AUTOSAR XML (schema 3-2-1)
package /SeatHeater/HeatRegulator_swc
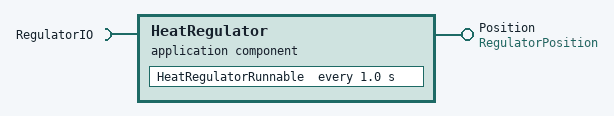
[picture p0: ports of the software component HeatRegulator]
  application software component type HeatRegulator
    provide port Position: unqueued-sender-com-spec{data-element=Position, alive-timeout=60.0}, provided-interface=RegulatorPosition
    require port RegulatorIO: unqueued-receiver-com-spec{data-element=RegulatorValue, alive-timeout=60.0}, required_interface=RegulatorIOInterface
  internal behavior HeatRegulatorBehavior: component=HeatRegulator
    timing event HeatRegulatorEvent: start-on-event=HeatRegulatorRunnable, period=1.0
    runnable HeatRegulatorRunnable: can-be-invoked-concurrently=true
      data read access HeatRegulatorIOAccess: data-element=RegulatorIO.RegulatorValue
      data write access HeatRegulatorPositionAccess: data-element=RegulatorPosition.Position
  swc implementation HeatRegulatorImplementation: behavior=HeatRegulatorBehavior
